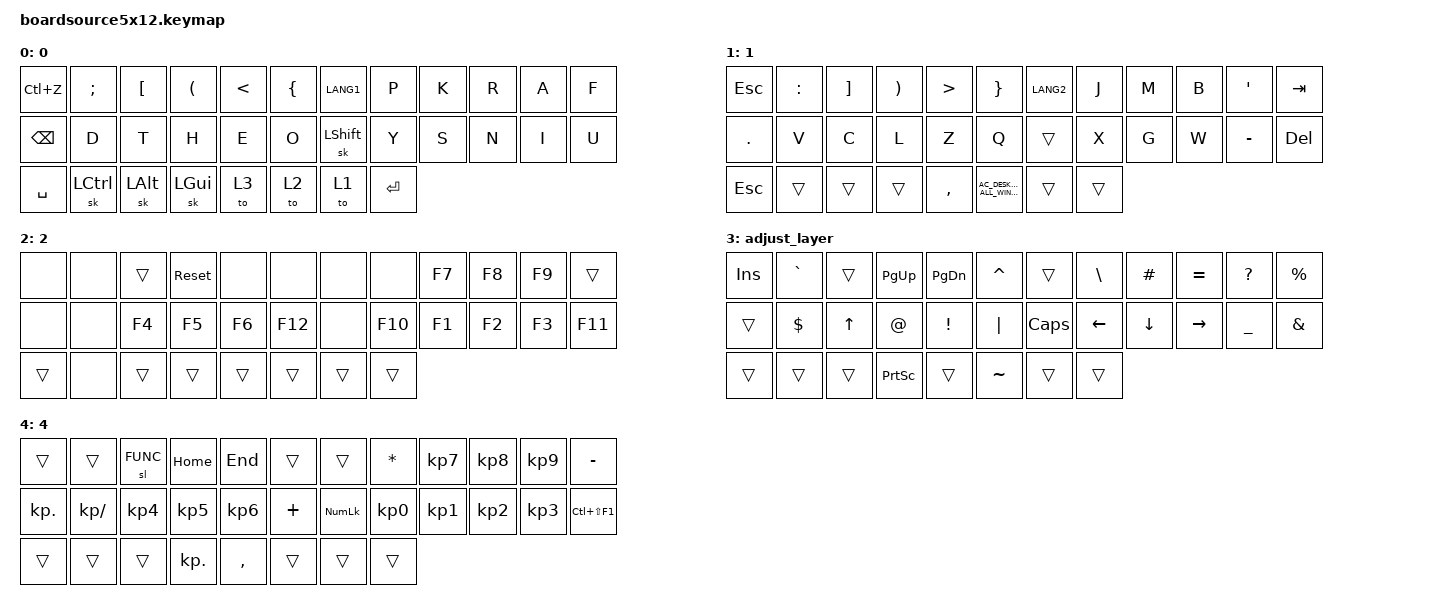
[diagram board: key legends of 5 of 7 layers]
/*
 * Copyright (c) 2021 The ZMK Contributors
 *
 * SPDX-License-Identifier: MIT
 */

#include <behaviors.dtsi>
#include <dt-bindings/zmk/keys.h>

/ {
    keymap {
        compatible = "zmk,keymap";

        default_layer {
            // ------------------------------------------------------------------------------------------
            // |  ESC  |  1   |  2   |  3   |  4   |  5   |   6   |  7    |  8   |  9   |   0   | BSPC  |
            // |  TAB  |  Q   |  W   |  E   |  R   |  T   |   Y   |  U    |  I   |  O   |   P   |  \    |
            // | SHIFT |  A   |  S   |  D   |  F   |  G   |   H   |  J    |  K   |  L   |   ;   |  '    |
            // | CTRL  |  Z   |  X   |  C   |  V   |  B   |   N   |  M    |  ,   |  .   |   /   | ENTER |
            // |ADJUST | LCTL | LALT | LGUI | LOWR | SPACE| SPACE |  RAIS | LEFT | DOWN | UARW  | RARW  |

            bindings = <
&kp LC(Z)  &kp SEMI   &kp LBKT  &kp LPAR  &kp LT  &kp LBRC  &kp LANG1  &kp P      &kp K  &kp R  &kp A  &kp F
&kp BSPC   &kp D      &kp T     &kp H     &kp E   &kp O     &sk LSHFT  &kp Y      &kp S  &kp N  &kp I  &kp U
&kp SPACE  &sk LCTRL  &sk LALT  &sk LGUI  &to 3   &to 2     &to 1      &kp ENTER
            >;

            label = "0";
        };

        lower_layer {
            // -------------------------------------------------------------------------------------------
            // |  ESC  |  F2  |  F3  |  F4  |  F5  |  F6  |   F7  |  F8   |  F9  | F10  |  F11  |  F12  |
            // |   ~   |  !   |  @   |  #   |  $   |  %   |   ^   |   &   |  *   |  (   |   )   |  DEL  |
            // |       |  F1  |  F2  |  F3  |  F4  |  F5  |   F6  |   _   |  +   |  {   |   }   |   |   |
            // |       |  F7  |  F8  |  F9  |  F10 |  F11 |   F12 | LS(#) |LS(|) |      |       |       |
            // |       |      |      |      |      |      |       |       | NEXT | Vol- | Vol+ | PLAY   |

            bindings = <
&kp ESC  &kp COLON  &kp RBKT  &kp RPAR  &kp GT     &kp RBRC                           &kp LANG2  &kp J   &kp M  &kp B  &kp SQT    &kp TAB
&kp DOT  &kp V      &kp C     &kp L     &kp Z      &kp Q                              &trans     &kp X   &kp G  &kp W  &kp MINUS  &kp DEL
&kp ESC  &trans     &trans    &trans    &kp COMMA  &kp C_AC_DESKTOP_SHOW_ALL_WINDOWS  &trans     &trans
            >;

            label = "1";
        };

        raise_layer {
            // ------------------------------------------------------------------------------------------
            // |  ESC  |  F2  |  F3  |  F4  |  F5  |  F6  |  F7   |  F8   |  F9  | F10  |  F11  |  F12  |
            // |   ~   |  1   |  2   |  3   |  4   |  5   |  6    |   7   |  8   |  9   |   0   |  DEL  |
            // |  DEL  |  F1  |  F2  |  F3  |  F4  |  F5  |  F6   |   -   |  =   |  [   |   ]   |   \   |
            // |       |  F7  |  F8  |  F9  |  F10 |  F11 |  F12  |   #   |  |   |      |       |       |
            // |       |      |      |      |      |      |       |       |       |      |      |       |

            bindings = <
&none   &none  &trans  &sys_reset  &none   &none    &none   &none    &kp F7  &kp F8  &kp F9  &trans
&none   &none  &kp F4  &kp F5      &kp F6  &kp F12  &none   &kp F10  &kp F1  &kp F2  &kp F3  &kp F11
&trans  &none  &trans  &trans      &trans  &trans   &trans  &trans
            >;

            label = "2";
        };

        adjust_layer {
            // ------------------------------------------------------------------------------------------
            // |tog(4)|  F2  |  F3  |  F4  |  F5  |  F6  |  F7  |  F8  |  F9  |  F10 |  F11 |    F12    |
            // |      |  NA  |  NA  |  NA  |  NA  |  NA  |  NA  |  NA  |  NA  |  NA  |  NA  |LALT(PRTSN)|
            // |      |  NA  |  NA  |  NA  |  NA  |  NA  |  NA  |  NA  |  NA  |  NA  |  NA  |   PRTSN   |
            // |      |  NA  |  NA  |  NA  |  NA  |  NA  |  NA  |  NA  |  NA  |  NA  |  NA  |LCTRL(DEL) |
            // |      |      |      |      |      |BOOTLD|BOOTLD|      |      |      |      |           |

            bindings = <
&kp INS  &kp GRAVE  &trans  &kp PG_UP  &kp PG_DN  &kp CARET  &trans    &kp BSLH  &kp HASH  &kp EQUAL  &kp QMARK  &kp PRCNT
&trans   &kp DLLR   &kp UP  &kp AT     &kp EXCL   &kp PIPE   &kp CAPS  &kp LEFT  &kp DOWN  &kp RIGHT  &kp UNDER  &kp AMPS
&trans   &trans     &trans  &kp PSCRN  &trans     &kp TILDE  &trans    &trans
            >;
        };

        flock_layer {
            // ----------------------------------------------------------------------------------------------
            // |tog(4) |  F2    |   F3   |   F4   |   F5   |   F6   |  F7  |  F8  |  F9  | F10 | F11 |      |
            // |out tog|BT_SEL 0|BT_SEL 1|BT_SEL 2|BT_SEL 3|BT_SEL 4|BT_PRV|BT_NXT|BT_CLR|     |     |      |
            // |       |        |        |        |        |        |      |      |      |     |     |      |
            // |       |        |        |        |        |        |      |      |      |     |     |      |
            // |       |        |        |        |        |        |      |      |      |     |     |      |

            bindings = <
&trans      &trans        &sl FUNC   &kp HOME    &kp END    &trans    &trans          &kp ASTRK  &kp KP_N7  &kp KP_N8  &kp KP_N9  &kp MINUS
&kp KP_DOT  &kp KP_SLASH  &kp KP_N4  &kp KP_N5   &kp KP_N6  &kp PLUS  &kp KP_NUMLOCK  &kp KP_N0  &kp KP_N1  &kp KP_N2  &kp KP_N3  &kp LC(LS(F1))
&trans      &trans        &trans     &kp KP_DOT  &kp COMMA  &trans    &trans          &trans
            >;

            label = "4";
        };

        layer_5 {
            bindings = <
&trans  &trans  &trans  &trans  &trans  &trans  &trans  &trans  &trans  &trans  &trans  &trans
&trans  &trans  &trans  &trans  &trans  &trans  &trans  &trans  &trans  &trans  &trans  &trans
&trans  &trans  &trans  &trans  &trans  &trans  &trans  &trans  &trans  &trans  &trans  &trans
&trans  &trans  &trans  &trans  &trans  &trans  &trans  &trans  &trans  &trans  &trans  &trans
&trans  &trans  &trans  &trans  &trans  &trans  &trans  &trans  &trans  &trans  &trans  &trans
            >;
        };

        layer_6 {
            bindings = <
&trans  &trans  &trans  &trans  &trans  &trans  &trans  &trans  &trans  &trans  &trans  &trans
&trans  &trans  &trans  &trans  &trans  &trans  &trans  &trans  &trans  &trans  &trans  &trans
&trans  &trans  &trans  &trans  &trans  &trans  &trans  &trans  &trans  &trans  &trans  &trans
&trans  &trans  &trans  &trans  &trans  &trans  &trans  &trans  &trans  &trans  &trans  &trans
&trans  &trans  &trans  &trans  &trans  &trans  &trans  &trans  &trans  &trans  &trans  &trans
            >;
        };
    };
};
